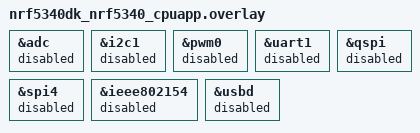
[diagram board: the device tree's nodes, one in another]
/*
 * Copyright (c) 2026 Nordic Semiconductor ASA
 *
 * SPDX-License-Identifier: LicenseRef-Nordic-5-Clause
 */

/* Disable unused peripherals to reduce power consumption */
&adc {
	status = "disabled";
};

&i2c1 {
	status = "disabled";
};

&pwm0 {
	status = "disabled";
};

&uart1 {
	status = "disabled";
};

&qspi {
	status = "disabled";
};

&spi4 {
	status = "disabled";
};

&ieee802154 {
	status = "disabled";
};

&usbd {
	status = "disabled";
};
